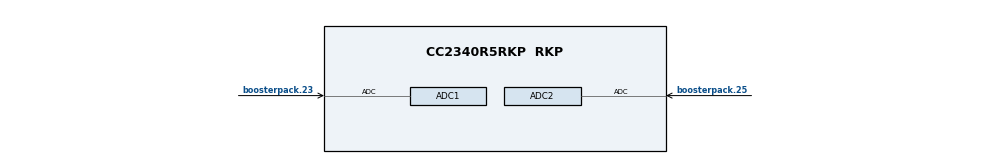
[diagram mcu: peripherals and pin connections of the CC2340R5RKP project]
/**
 * @cliArgs --board "/ti/boards/LP_EM_CC2340R5" --device "CC2340R5RKP" --part "Default" --package "RKP" --rtos "freertos" --product "simplelink_lowpower_f3_sdk@9.11.00.18"
 * @versions {"tool":"1.23.2+4156"}
 */

/**
 * Import the modules used in this configuration.
 */
const FreeRTOS = scripting.addModule("/freertos/FreeRTOS");
const Display  = scripting.addModule("/ti/display/Display");
const Display1 = Display.addInstance();
const ADC      = scripting.addModule("/ti/drivers/ADC");
const ADC1     = ADC.addInstance();
const ADC2     = ADC.addInstance();
const Settings = scripting.addModule("/ti/posix/freertos/Settings");

/**
 * Write custom configuration values to the imported modules.
 */
Display1.$name      = "CONFIG_Display_0";
Display1.$hardware  = system.deviceData.board.components.XDS110UART;
Display1.uart.$name = "CONFIG_UART2_0";

ADC1.$name                         = "CONFIG_ADC_0";
ADC1.adcChannel.adc.adcPin.$assign = "boosterpack.23";

ADC2.$name                         = "CONFIG_ADC_1";
ADC2.adcChannel.adc.adcPin.$assign = "boosterpack.25";

const CCFG              = scripting.addModule("/ti/devices/CCFG", {}, false);
CCFG.ccfgTemplate.$name = "ti_devices_CCFG_CCFGCC23X0Template0";

/**
 * Pinmux solution for unlocked pins/peripherals. This ensures that minor changes to the automatic solver in a future
 * version of the tool will not impact the pinmux you originally saw.  These lines can be completely deleted in order to
 * re-solve from scratch.
 */
Display1.uart.uart.$suggestSolution              = "UART0";
Display1.uart.uart.dmaTxChannel.$suggestSolution = "DMA_CH1";
Display1.uart.uart.dmaRxChannel.$suggestSolution = "DMA_CH0";
Display1.uart.uart.txPin.$suggestSolution        = "boosterpack.4";
Display1.uart.uart.rxPin.$suggestSolution        = "boosterpack.3";
ADC1.adcChannel.adc.$suggestSolution             = "ADC";
ADC2.adcChannel.adc.$suggestSolution             = "ADC";
